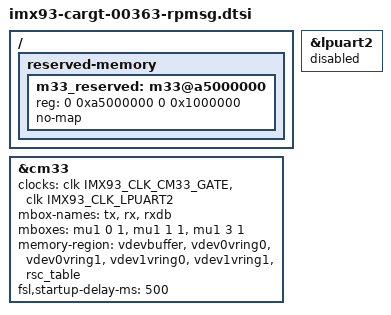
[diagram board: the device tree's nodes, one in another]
// SPDX-License-Identifier: (GPL-2.0+ OR MIT)
/*
 * Copyright 2026 Cargt
 *
 * Cortex-M33 remoteproc and RPMsg for the i.MX 93 00363 SOM.
 *
 * Linux can then start and stop M33 firmware from
 * /sys/class/remoteproc/remoteproc0 and talk to it over RPMsg (virtio vrings
 * in DDR, MU1 for the doorbells). The vring, vdev buffer and resource table
 * regions are already reserved in imx93-cargt-00363-osm-som.dts; this adds
 * the M33's 16 MB DDR region at 0xa5000000, as NXP's i.MX 93 EVK does, so
 * Linux never uses it and M33 firmware can keep its data there at run time.
 * remoteproc loads the firmware image itself into the M33 TCM: the i.MX 93
 * address table in imx_rproc does not map 0xa5000000, so an ELF linked to
 * run from this region cannot be loaded by Linux.
 *
 * NXP's i.MX 93 EVK firmware in /lib/firmware (rpmsg_lite_str_echo,
 * rpmsg_lite_pingpong, ...) uses LPUART2 as its debug console, and on the
 * 00363 that is the mikroBUS UART (pads UART2_TXD/UART2_RXD), so Linux gives
 * LPUART2 up here. Firmware built for the 00363 can use another UART instead.
 *
 * Firmware can be started from Linux remoteproc
 * (echo start > /sys/class/remoteproc/remoteproc0/state), or by U-Boot bootaux
 * and then attached by Linux. With bootaux the firmware is already running
 * when Linux turns off clocks no Linux driver uses (clk_disable_unused), so
 * every clock the firmware needs is listed on &cm33: imx_rproc keeps the
 * clocks after the first one enabled (linux-imx patch 0018). Without
 * LPUART2's, the EVK demos stop at their first print, and RPMsg writes from
 * Linux hang. Firmware that uses other peripherals Linux does not drive needs
 * their clocks added here too.
 *
 * IMX93_CLK_LPUART2 is LPUART2's clock root, not its LPCG gate
 * (IMX93_CLK_LPUART2_GATE), and the root is what has to be held. The root has
 * one on/off control, so clk_disable_unused really gates it. The LPCG runs in
 * CPU low-power mode (CPULPM_EN in its AUTHEN register), where each domain has
 * its own on/off setting: Linux turning it off only clears Linux's setting, and
 * the M33's own setting keeps the gate running. Checked with bootaux and
 * rpmsg_lite_str_echo: clk_summary shows lpuart2_root enabled for
 * remoteproc-cm33 and lpuart2 as off (Linux's setting), and the M33 echoes
 * RPMsg tty writes long after "clk: Disabling unused clocks".
 */

/ {
	reserved-memory {
		m33_reserved: m33@a5000000 {
			reg = <0 0xa5000000 0 0x1000000>;
			no-map;
		};
	};
};

&cm33 {
	clocks = <&clk IMX93_CLK_CM33_GATE>, <&clk IMX93_CLK_LPUART2>;
	mbox-names = "tx", "rx", "rxdb";
	mboxes = <&mu1 0 1>,
		 <&mu1 1 1>,
		 <&mu1 3 1>;
	memory-region = <&vdevbuffer>, <&vdev0vring0>, <&vdev0vring1>,
			<&vdev1vring0>, <&vdev1vring1>, <&rsc_table>;
	fsl,startup-delay-ms = <500>;
	status = "okay";
};

/* The M33 firmware's debug console (mikroBUS UART) */
&lpuart2 {
	status = "disabled";
};
